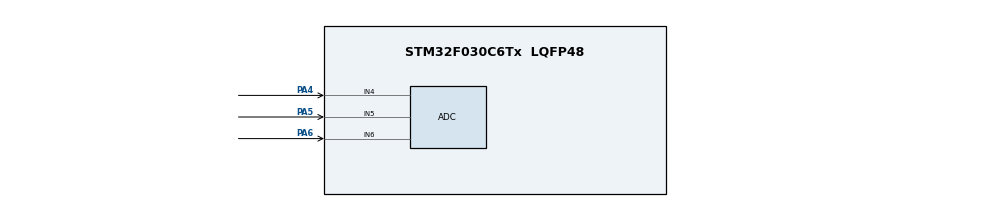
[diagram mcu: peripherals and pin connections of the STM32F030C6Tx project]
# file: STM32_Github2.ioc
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Mcu.Family=STM32F0
Mcu.Name=STM32F030C6Tx
Mcu.Package=LQFP48
PA13.Mode=Serial_Wire
PA13.Signal=SYS_SWDIO
PA14.Mode=Serial_Wire
PA14.Signal=SYS_SWCLK
PA4.Mode=IN4
PA4.Signal=ADC_IN4
PA5.Mode=IN5
PA5.Signal=ADC_IN5
PA6.Mode=IN6
PA6.Signal=ADC_IN6
ProjectManager.HeapSize=0x200
ProjectManager.StackSize=0x400
ProjectManager.TargetToolchain=STM32CubeIDE
board=custom

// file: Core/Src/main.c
/* USER CODE BEGIN Header */
/**
  ******************************************************************************
  * @file           : main.c
  * @brief          : Main program body
  ******************************************************************************
  * @attention
  *
  * Copyright (c) 2025 STMicroelectronics.
  * All rights reserved.
  *
  * This software is licensed under terms that can be found in the LICENSE file
  * in the root directory of this software component.
  * If no LICENSE file comes with this software, it is provided AS-IS.
  *
  ******************************************************************************
  */
/* USER CODE END Header */
#include "main.h"

/* USER CODE BEGIN PD */

uint16_t baslangicComptoGithub=0;
uint16_t GithubtoComp=0;           // Githubtan bilgisayara ilk veri transferi
uint16_t ComptoGithub=0;           // Bilgisayardan githuba veri transferi

uint16_t YeniBranch_ComptoBranch=0;    	// Yeni-Özellik branchine ilk değişken bilgisayardan eklendi.
uint16_t YeniBranch_GithubtoComp=0;     // Yeni-Özellik branchine githubtan yeni bir değişken eklendi.

uint16_t ForkDeneme1_Comp=0;			  // Forka ekleme denemesi sonrası bilgisayardan eklendi.
uint16_t ForkDeneme2_Github=0;			// Forka ekleme denemesi sonrası Githubtan eklendi.
uint16_t ForkDeneme3_Github=0;			// Forka ekleme denemesi sonrası Githubtan eklendi.
uint16_t ForkDeneme4_Github=0;			// Forka ekleme denemesi sonrası Githubtan eklendi.

uint16_t YeniBranch_Fork_Comp=0;	  	// Forka ekleme denemesi sonrası bilgisayardan eklendi.
uint16_t YeniBranch_Fork_Github=0;		// Forka ekleme denemesi sonrası Githubtan eklendi.
/* USER CODE END PD */

ADC_HandleTypeDef hadc;

void SystemClock_Config(void);
static void MX_GPIO_Init(void);
static void MX_ADC_Init(void);

int main(void)
{

  /* MCU Configuration--------------------------------------------------------*/

  /* Reset of all peripherals, Initializes the Flash interface and the Systick. */
  HAL_Init();

  /* Configure the system clock */
  SystemClock_Config();

  /* Initialize all configured peripherals */
  MX_GPIO_Init();
  MX_ADC_Init();

  /* Infinite loop */
  while (1)
  {

  }
}

void SystemClock_Config(void)
{
  RCC_OscInitTypeDef RCC_OscInitStruct = {0};
  RCC_ClkInitTypeDef RCC_ClkInitStruct = {0};

  /** Initializes the RCC Oscillators according to the specified parameters
  * in the RCC_OscInitTypeDef structure.
  */
  RCC_OscInitStruct.OscillatorType = RCC_OSCILLATORTYPE_HSI|RCC_OSCILLATORTYPE_HSI14;
  RCC_OscInitStruct.HSIState = RCC_HSI_ON;
  RCC_OscInitStruct.HSI14State = RCC_HSI14_ON;
  RCC_OscInitStruct.HSICalibrationValue = RCC_HSICALIBRATION_DEFAULT;
  RCC_OscInitStruct.HSI14CalibrationValue = 16;
  RCC_OscInitStruct.PLL.PLLState = RCC_PLL_NONE;
  if (HAL_RCC_OscConfig(&RCC_OscInitStruct) != HAL_OK)
  {
    Error_Handler();
  }

  /** Initializes the CPU, AHB and APB buses clocks
  */
  RCC_ClkInitStruct.ClockType = RCC_CLOCKTYPE_HCLK|RCC_CLOCKTYPE_SYSCLK
                              |RCC_CLOCKTYPE_PCLK1;
  RCC_ClkInitStruct.SYSCLKSource = RCC_SYSCLKSOURCE_HSI;
  RCC_ClkInitStruct.AHBCLKDivider = RCC_SYSCLK_DIV1;
  RCC_ClkInitStruct.APB1CLKDivider = RCC_HCLK_DIV1;

  if (HAL_RCC_ClockConfig(&RCC_ClkInitStruct, FLASH_LATENCY_0) != HAL_OK)
  {
    Error_Handler();
  }
}

static void MX_ADC_Init(void)
{

  ADC_ChannelConfTypeDef sConfig = {0};

  /** Configure the global features of the ADC (Clock, Resolution, Data Alignment and number of conversion)
  */
  hadc.Instance = ADC1;
  hadc.Init.ClockPrescaler = ADC_CLOCK_ASYNC_DIV1;
  hadc.Init.Resolution = ADC_RESOLUTION_12B;
  hadc.Init.DataAlign = ADC_DATAALIGN_RIGHT;
  hadc.Init.ScanConvMode = ADC_SCAN_DIRECTION_FORWARD;
  hadc.Init.EOCSelection = ADC_EOC_SINGLE_CONV;
  hadc.Init.LowPowerAutoWait = DISABLE;
  hadc.Init.LowPowerAutoPowerOff = DISABLE;
  hadc.Init.ContinuousConvMode = DISABLE;
  hadc.Init.DiscontinuousConvMode = DISABLE;
  hadc.Init.ExternalTrigConv = ADC_SOFTWARE_START;
  hadc.Init.ExternalTrigConvEdge = ADC_EXTERNALTRIGCONVEDGE_NONE;
  hadc.Init.DMAContinuousRequests = DISABLE;
  hadc.Init.Overrun = ADC_OVR_DATA_PRESERVED;
  if (HAL_ADC_Init(&hadc) != HAL_OK)
  {
    Error_Handler();
  }

  /** Configure for the selected ADC regular channel to be converted.
  */
  sConfig.Channel = ADC_CHANNEL_4;
  sConfig.Rank = ADC_RANK_CHANNEL_NUMBER;
  sConfig.SamplingTime = ADC_SAMPLETIME_1CYCLE_5;
  if (HAL_ADC_ConfigChannel(&hadc, &sConfig) != HAL_OK)
  {
    Error_Handler();
  }

  /** Configure for the selected ADC regular channel to be converted.
  */
  sConfig.Channel = ADC_CHANNEL_5;
  if (HAL_ADC_ConfigChannel(&hadc, &sConfig) != HAL_OK)
  {
    Error_Handler();
  }

  /** Configure for the selected ADC regular channel to be converted.
  */
  sConfig.Channel = ADC_CHANNEL_6;
  if (HAL_ADC_ConfigChannel(&hadc, &sConfig) != HAL_OK)
  {
    Error_Handler();
  }

}

static void MX_GPIO_Init(void)
{

  /* GPIO Ports Clock Enable */
  __HAL_RCC_GPIOA_CLK_ENABLE();

}

void Error_Handler(void)
{
  __disable_irq();
  while (1)
  {
  }
}
